VERSION ""

NS_ :

BS_:

BU_: ControlUnit HospitalBed
VAL_TABLE_ OnOff 0 "Off" -1290070 "On" ;
VAL_TABLE_ SVariant 1 "Comfort" 0 "Basis" ;

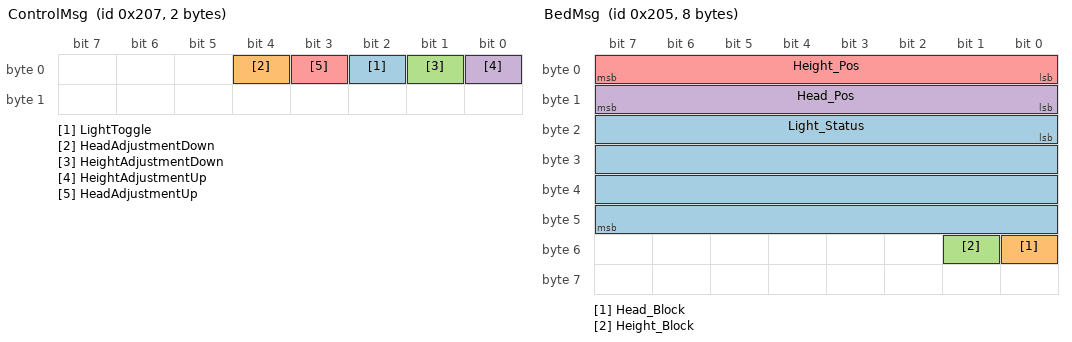
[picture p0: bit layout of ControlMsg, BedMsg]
BO_ 519 ControlMsg: 2 ControlUnit
 SG_ LightToggle : 2|1@1+ (1,0) [0|1] "" Vector__XXX
 SG_ HeadAdjustmentDown : 4|1@1+ (1,0) [0|1] "" Vector__XXX
 SG_ HeightAdjustmentDown : 1|1@1+ (1,0) [0|1] "" Vector__XXX
 SG_ HeightAdjustmentUp : 0|1@1+ (1,0) [0|1] ""  HospitalBed
 SG_ HeadAdjustmentUp : 3|1@1+ (1,0) [0|1] ""  HospitalBed

BO_ 517 BedMsg: 8 HospitalBed
 SG_ Light_Status : 16|32@1+ (1,0) [0|0] "" Vector__XXX
 SG_ Head_Block : 48|1@1+ (1,0) [0|1] ""  ControlUnit
 SG_ Height_Block : 49|1@1+ (1,0) [0|1] ""  ControlUnit
 SG_ Head_Pos : 8|8@1+ (1,0) [0|255] ""  ControlUnit
 SG_ Height_Pos : 0|8@1+ (1,0) [0|255] ""  ControlUnit

BA_DEF_ SG_  "GenSigSendType" ENUM  "Cyclic","OnWrite","OnWriteWithRepetition","OnChange";
BA_DEF_ BO_  "GenMsgILSupport" ENUM  "No","Yes";
BA_DEF_ BU_  "ILUsed" ENUM  "Yes","No";
BA_DEF_ BO_  "GenMsgSendType" ENUM  "Cyclic","NotUsed","NotUsed","NotUsed","NotUsed","Cyclic","NotUsed","IfActive","NoMsgSendType","NotUsed";
BA_DEF_ BO_  "GenMsgStartDelayTime" INT 0 0;
BA_DEF_ BO_  "GenMsgCycleTime" INT 0 0;
BA_DEF_  "BusType" STRING ;
BA_DEF_ BU_  "NodeLayerModules" STRING ;
BA_DEF_DEF_  "GenSigSendType" "Cyclic";
BA_DEF_DEF_  "GenMsgILSupport" "Yes";
BA_DEF_DEF_  "ILUsed" "Yes";
BA_DEF_DEF_  "GenMsgSendType" "NoMsgSendType";
BA_DEF_DEF_  "GenMsgStartDelayTime" 0;
BA_DEF_DEF_  "GenMsgCycleTime" 0;
BA_DEF_DEF_  "BusType" "CAN";
BA_DEF_DEF_  "NodeLayerModules" "CANoeILNLVector.dll";
BA_ "NodeLayerModules" BU_ HospitalBed "CANoeILNLVector.dll,osek_tp.dll";
BA_ "GenMsgCycleTime" BO_ 519 100;
BA_ "GenMsgSendType" BO_ 519 0;
BA_ "GenMsgCycleTime" BO_ 517 100;
BA_ "GenMsgStartDelayTime" BO_ 517 50;
BA_ "GenSigSendType" SG_ 519 HeadAdjustmentDown 3;
BA_ "GenSigSendType" SG_ 519 HeightAdjustmentDown 3;
BA_ "GenSigSendType" SG_ 519 HeightAdjustmentUp 3;
BA_ "GenSigSendType" SG_ 519 HeadAdjustmentUp 3;
VAL_ 517 Light_Status 0 "Off" -1290070 "On" ;
